# MSP430FR2355 register map
Vendor: msp430gen; File version: v0.4.0-28-gb0087ce-dirty
Registers are 16-bit, read-write, reset 0x0 unless marked. A register's access mark holds for its fields unless they carry their own. Offsets are from the block's base; [hi:lo] are bit positions; {n}, {i} and the like mark numbered series; 'fields as' and 'values as' point back to an identical list.

## FRCTL
Base 0x000001A0
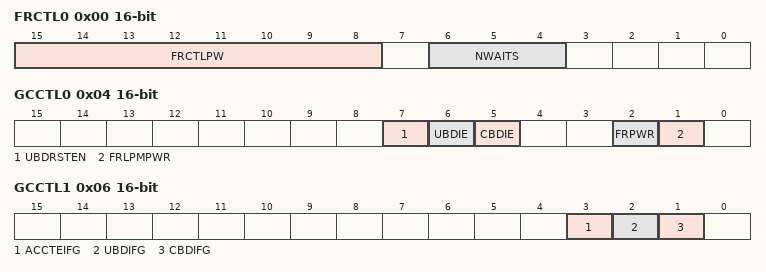
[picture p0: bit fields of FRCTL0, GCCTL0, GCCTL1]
0x00 FRCTL0 — FRAM Controller Control Register 0
  [15:8] FRCTLPW — FRCTLPW password
    on read: 150=PASSWORD (Value always read from the FRCTL0 password) | on write: 165=PASSWORD (Value which must be written to the FRCTL0 password)
  [6:4] NWAITS — Wait state numbers
    0=WAIT0 (No wait state); 1=WAIT1 (1 wait state); {v}=WAIT{v} ({v} wait states) (v=2..7)
0x01 FRCTL0_H 8-bit (alternate view of FRCTL0) — FRAM Controller Control Register 0, upper byte
  [7:0] FRCTLPW — FRAM controller password
    on read: 150=PASSWORD (Value always read from the FRCTL0 password) | on write: 0=LOCK (Locks the FRAM controller registers again); 165=PASSWORD (Unlocks the FRAM controller registers)
0x04 GCCTL0 — General Control Register 0
  [7] UBDRSTEN — Enable Power Up Clear (PUC) reset for the uncorrectable bit error detection flag (UBDIFG)
    0=PUC not initiated on uncorrectable bit error detection flag; 1=PUC initiated on uncorrectable bit error detection flag. Generates vector in SYSRSTIV. Clear the UBDIE bit.
  [6] UBDIE — Enable NMI event for the uncorrectable bit error detection flag (UBDIFG)
    0=Disable NMI for the uncorrectable bit error detection flag (UBDIFG); 1=Enable NMI for the uncorrectable bit error detection flag (UBDIFG). Generates vector in SYSSNIV. Clear the UBDRSTEN bit.
  [5] CBDIE — Enable NMI event for the correctable bit error detection flag (CBDIFG)
    0=Disable NMI for the correctable bit error detection flag (CBDIFG); 1=Disable NMI for the correctable bit error detection flag (CBDIFG). Generates vector in SYSSNIV.
  [2] FRPWR — FRAM Memory Power Control Request
    0=DISABLED (FRAM power supply disabled); 1=ENABLED (FRAM power supply enabled)
  [1] FRLPMPWR ro — Enables FRAM auto power up after LPM
    0=FRAM startup is delayed to the first FRAM access after exit from LPM; 1=FRAM is powered up immediately on exit from LPM
0x06 GCCTL1 — General Control Register 1
  [3] ACCTEIFG — Access time error flag
    0=No interrupt pending; 1=Interrupt pending. Can be cleared by writing '0' or by reading SYSSNIV when it is the highest pending interrupt.
  [2] UBDIFG — FRAM uncorrectable bit error detection flag
    values as ACCTEIFG
  [1] CBDIFG — FRAM correctable bit error detection flag
    0=No interrupt is pending; 1=Interrupt pending. Can be cleared by writing '0' or by reading SYSSNIV if it is the highest pending interrupt.

## CRC
Base 0x000001C0
0x00 CRCDI — CRC Data In
  [15:0] CRCDI — CRC data in
0x00 CRCDI_L 8-bit (alternate view of CRCDI) — CRC Data In Register, lower byte
  [7:0] CRCDI — CRC data in, one byte
0x02 CRCDIRB — CRC Data In Reverse Byte
  [15:0] CRCDIRB — CRC data in, bits reversed
0x02 CRCDIRB_L 8-bit (alternate view of CRCDIRB) — CRC Data In Reverse Byte Register, lower byte
  [7:0] CRCDIRB — CRC data in, one byte, bits reversed
0x04 CRCINIRES — CRC Initialization and Result
  [15:0] CRCINIRES — CRC initialization (on write) and result (on read)
0x06 CRCRESR — CRC Result Reverse
  [15:0] CRCRESR ro — CRC result, bits reversed

## WDT_A
Base 0x000001CC
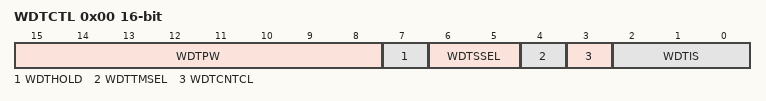
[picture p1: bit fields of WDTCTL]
0x00 WDTCTL — Watchdog Timer Control Register
  [15:8] WDTPW — Watchdog timer password
    on read: 105=PASSWORD (Value always read from the Watchdog Password field) | on write: 90=PASSWORD (Value which must be written to the Watchdog Password field)
  [7] WDTHOLD — Watchdog timer hold
    0=UNHOLD (Watchdog timer is not stopped); 1=HOLD (Watchdog timer is stopped)
  [6:5] WDTSSEL — Watchdog timer clock source select
    0=SMCLK; 1=ACLK; 2=VLOCLK; 3=BCLK
  [4] WDTTMSEL — Watchdog timer mode select
    0=Watchdog mode; 1=Interval timer mode
  [3] WDTCNTCL — Watchdog timer counter clear
    0=No action; 1=WDTCNT = 0000h
  [2:0] WDTIS — Watchdog timer interval select
    0=2G (Watchdog clock source / (2^(31)) (18:12:16 at 32.768 kHz)); 1=128M (Watchdog clock source /(2^(27)) (01:08:16 at 32.768 kHz)); 2=8192K (Watchdog clock source /(2^(23)) (00:04:16 at 32.768 kHz)); 3=512K (Watchdog clock source /(2^(19)) (00:00:16 at 32.768 kHz)); 4=32K (Watchdog clock source /(2^(15)) (1 s at 32.768 kHz)); 5=Watchdog clock source / (2^(13)) (250 ms at 32.768 kHz); 6=Watchdog clock source / (2^(9)) (15.625 ms at 32.768 kHz); 7=Watchdog clock source / (2^(6)) (1.95 ms at 32.768 kHz)
